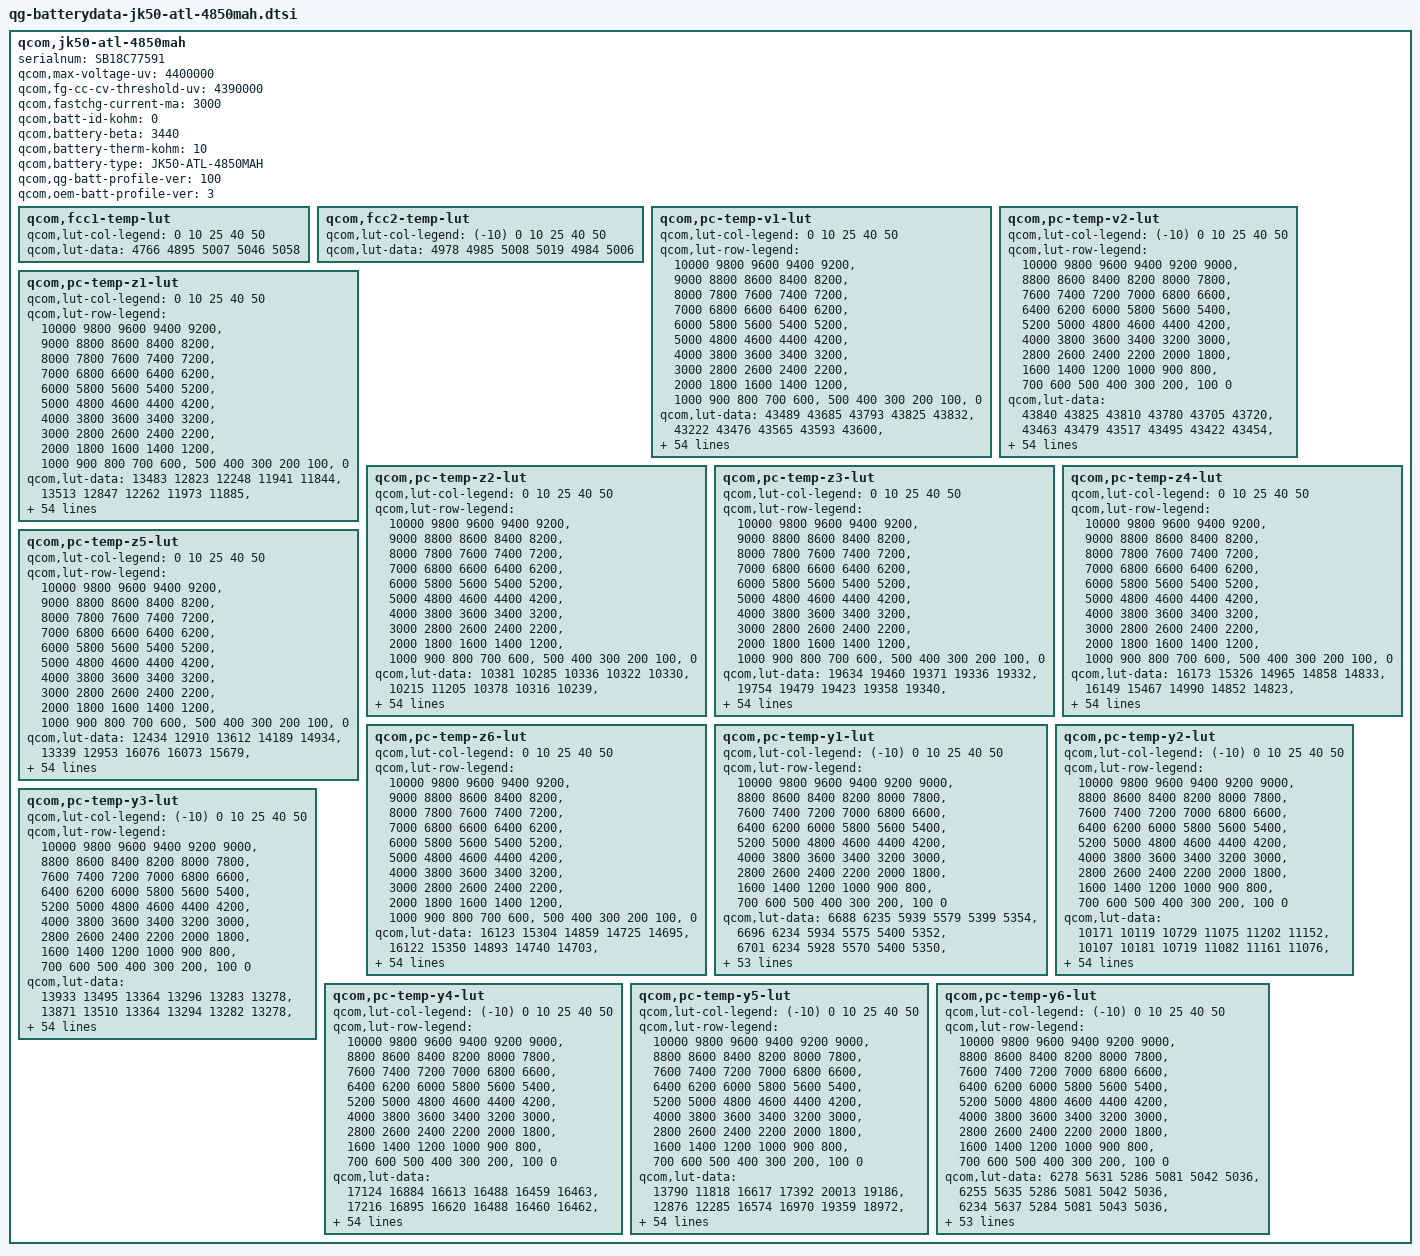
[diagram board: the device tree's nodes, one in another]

qcom,jk50-atl-4850mah {
    /* 4456891_ATL_P270AE_SCUD_4850mAH_PMI632_averaged_MasterSlave_Apr8th2020 */
    serialnum = "SB18C77591";
    qcom,max-voltage-uv = <4400000>;
    qcom,fg-cc-cv-threshold-uv = <4390000>;
    qcom,fastchg-current-ma = <3000>;
    qcom,batt-id-kohm = <0>;
    qcom,battery-beta = <3440>;
    qcom,battery-therm-kohm = <10>;
    qcom,battery-type = "JK50-ATL-4850MAH";
    qcom,qg-batt-profile-ver = <100>;
    qcom,oem-batt-profile-ver = <3>;

	qcom,fcc1-temp-lut {
		qcom,lut-col-legend = <0 10 25 40 50>;
		qcom,lut-data = <4766 4895 5007 5046 5058>;
	};

	qcom,fcc2-temp-lut {
		qcom,lut-col-legend = <(-10) 0 10 25 40 50>;
		qcom,lut-data = <4978 4985 5008 5019 4984 5006>;
	};

	qcom,pc-temp-v1-lut {
		qcom,lut-col-legend = <0 10 25 40 50>;
		qcom,lut-row-legend = <10000 9800 9600 9400 9200>,
			<9000 8800 8600 8400 8200>,
			<8000 7800 7600 7400 7200>,
			<7000 6800 6600 6400 6200>,
			<6000 5800 5600 5400 5200>,
			<5000 4800 4600 4400 4200>,
			<4000 3800 3600 3400 3200>,
			<3000 2800 2600 2400 2200>,
			<2000 1800 1600 1400 1200>,
			<1000 900 800 700 600>,
			<500 400 300 200 100>,
			<0>;
		qcom,lut-data = <43489 43685 43793 43825 43832>,
			<43222 43476 43565 43593 43600>,
			<42969 43219 43335 43369 43384>,
			<42729 42960 43094 43140 43159>,
			<42498 42718 42852 42907 42927>,
			<42272 42482 42613 42674 42696>,
			<42050 42251 42378 42440 42464>,
			<41833 42025 42145 42206 42233>,
			<41616 41803 41915 41975 42002>,
			<41407 41581 41689 41747 41772>,
			<41218 41366 41466 41521 41546>,
			<41046 41172 41250 41300 41326>,
			<40852 40998 41044 41086 41109>,
			<40601 40807 40847 40883 40898>,
			<40340 40566 40644 40681 40692>,
			<40134 40321 40429 40471 40491>,
			<39963 40127 40224 40267 40298>,
			<39809 39962 40050 40090 40118>,
			<39671 39812 39892 39931 39950>,
			<39543 39678 39739 39773 39785>,
			<39416 39547 39597 39618 39628>,
			<39293 39401 39429 39449 39462>,
			<39172 39246 39164 39216 39242>,
			<39053 39071 38884 38950 38983>,
			<38937 38840 38735 38781 38807>,
			<38821 38633 38640 38678 38699>,
			<38703 38527 38560 38589 38606>,
			<38594 38455 38486 38499 38507>,
			<38498 38398 38419 38414 38413>,
			<38410 38351 38354 38332 38326>,
			<38347 38310 38295 38255 38245>,
			<38301 38270 38241 38187 38172>,
			<38262 38233 38191 38130 38109>,
			<38227 38198 38145 38077 38050>,
			<38196 38167 38101 38023 37992>,
			<38163 38134 38058 37971 37936>,
			<38131 38098 38014 37920 37878>,
			<38094 38058 37971 37874 37822>,
			<38042 38002 37915 37817 37757>,
			<37969 37917 37827 37732 37668>,
			<37880 37814 37718 37624 37560>,
			<37760 37698 37604 37509 37444>,
			<37622 37562 37477 37380 37314>,
			<37464 37402 37322 37228 37162>,
			<37330 37256 37176 37087 37022>,
			<37233 37167 37080 36996 36939>,
			<37204 37137 37056 36967 36911>,
			<37178 37114 37037 36951 36892>,
			<37159 37099 37022 36933 36871>,
			<37110 37052 36975 36873 36806>,
			<36889 36824 36740 36623 36542>,
			<36444 36392 36311 36185 36099>,
			<35865 35818 35740 35608 35527>,
			<35077 35035 34961 34821 34744>,
			<33839 33806 33753 33601 33539>,
			<30000 30000 30000 30000 30000>;
	};

	qcom,pc-temp-v2-lut {
		qcom,lut-col-legend = <(-10) 0 10 25 40 50>;
		qcom,lut-row-legend = <10000 9800 9600 9400 9200 9000>,
			<8800 8600 8400 8200 8000 7800>,
			<7600 7400 7200 7000 6800 6600>,
			<6400 6200 6000 5800 5600 5400>,
			<5200 5000 4800 4600 4400 4200>,
			<4000 3800 3600 3400 3200 3000>,
			<2800 2600 2400 2200 2000 1800>,
			<1600 1400 1200 1000 900 800>,
			<700 600 500 400 300 200>,
			<100 0>;
		qcom,lut-data = <43840 43825 43810 43780 43705 43720>,
			<43463 43479 43517 43495 43422 43454>,
			<43120 43162 43238 43225 43155 43197>,
			<42814 42878 42975 42971 42904 42952>,
			<42537 42625 42728 42733 42668 42718>,
			<42295 42378 42485 42497 42435 42485>,
			<42098 42133 42245 42263 42201 42251>,
			<41907 41893 42009 42030 41970 42018>,
			<41651 41655 41779 41800 41742 41789>,
			<41347 41421 41553 41573 41517 41562>,
			<41151 41211 41334 41348 41296 41339>,
			<41063 41036 41124 41129 41077 41120>,
			<40966 40861 40919 40914 40864 40905>,
			<40674 40665 40722 40711 40663 40698>,
			<40191 40451 40526 40512 40468 40497>,
			<39844 40198 40321 40307 40275 40303>,
			<39603 39874 40109 40096 40079 40116>,
			<39403 39591 39891 39905 39896 39938>,
			<39234 39410 39661 39754 39738 39773>,
			<39085 39260 39432 39605 39586 39610>,
			<38920 39094 39227 39404 39400 39422>,
			<38741 38920 39037 39156 39174 39210>,
			<38584 38758 38867 38941 38965 39009>,
			<38454 38616 38711 38764 38779 38814>,
			<38342 38481 38572 38612 38616 38641>,
			<38255 38341 38452 38489 38488 38510>,
			<38184 38199 38346 38385 38383 38402>,
			<38117 38102 38246 38288 38288 38302>,
			<38053 38041 38152 38199 38202 38211>,
			<37992 37993 38065 38117 38124 38127>,
			<37936 37946 37984 38043 38053 38054>,
			<37882 37903 37911 37973 37987 37985>,
			<37828 37860 37858 37908 37923 37920>,
			<37772 37816 37817 37847 37860 37858>,
			<37716 37772 37779 37789 37794 37788>,
			<37656 37727 37741 37734 37715 37697>,
			<37592 37679 37702 37676 37629 37598>,
			<37525 37624 37658 37610 37547 37501>,
			<37452 37561 37607 37536 37466 37406>,
			<37380 37490 37543 37459 37385 37318>,
			<37312 37405 37455 37379 37308 37242>,
			<37243 37307 37347 37283 37220 37155>,
			<37175 37192 37216 37157 37107 37047>,
			<37103 37070 37080 37023 36975 36909>,
			<37019 36957 36947 36912 36862 36799>,
			<36927 36856 36869 36872 36817 36761>,
			<36870 36817 36837 36848 36804 36749>,
			<36813 36776 36801 36829 36788 36737>,
			<36736 36725 36754 36783 36764 36709>,
			<36596 36632 36658 36647 36687 36617>,
			<36345 36426 36430 36288 36414 36304>,
			<35926 36021 35974 35763 35937 35816>,
			<35317 35415 35343 35066 35318 35179>,
			<34420 34552 34477 34037 34481 34304>,
			<33052 33166 33168 32764 33241 33030>,
			<28345 27965 27983 27933 28174 28632>;
	};

	qcom,pc-temp-z1-lut {
		qcom,lut-col-legend = <0 10 25 40 50>;
		qcom,lut-row-legend = <10000 9800 9600 9400 9200>,
			<9000 8800 8600 8400 8200>,
			<8000 7800 7600 7400 7200>,
			<7000 6800 6600 6400 6200>,
			<6000 5800 5600 5400 5200>,
			<5000 4800 4600 4400 4200>,
			<4000 3800 3600 3400 3200>,
			<3000 2800 2600 2400 2200>,
			<2000 1800 1600 1400 1200>,
			<1000 900 800 700 600>,
			<500 400 300 200 100>,
			<0>;
		qcom,lut-data = <13483 12823 12248 11941 11844>,
			<13513 12847 12262 11973 11885>,
			<13517 12846 12273 11976 11893>,
			<13493 12843 12259 11973 11890>,
			<13470 12841 12245 11968 11887>,
			<13462 12839 12235 11964 11886>,
			<13455 12834 12226 11962 11885>,
			<13448 12813 12218 11960 11885>,
			<13441 12795 12210 11958 11886>,
			<13435 12787 12206 11956 11887>,
			<13436 12779 12203 11956 11889>,
			<13443 12774 12200 11958 11892>,
			<13440 12764 12198 11958 11893>,
			<13400 12754 12196 11956 11893>,
			<13354 12743 12193 11955 11893>,
			<13342 12733 12189 11955 11892>,
			<13341 12728 12187 11957 11892>,
			<13342 12720 12188 11959 11893>,
			<13343 12717 12191 11961 11895>,
			<13342 12720 12195 11962 11896>,
			<13337 12727 12201 11963 11897>,
			<13324 12735 12205 11963 11898>,
			<13317 12748 12206 11965 11899>,
			<13317 12753 12206 11968 11901>,
			<13318 12749 12208 11970 11902>,
			<13322 12746 12214 11972 11904>,
			<13339 12748 12220 11974 11906>,
			<13352 12754 12225 11976 11909>,
			<13354 12757 12230 11979 11913>,
			<13356 12759 12234 11983 11916>,
			<13357 12761 12238 11988 11919>,
			<13357 12766 12242 11993 11923>,
			<13357 12776 12247 11998 11926>,
			<13361 12781 12252 12002 11930>,
			<13365 12786 12259 12005 11933>,
			<13370 12789 12267 12008 11937>,
			<13376 12793 12274 12011 11941>,
			<13383 12799 12281 12016 11944>,
			<13390 12807 12288 12022 11947>,
			<13409 12816 12295 12026 11950>,
			<13420 12828 12301 12031 11953>,
			<13436 12847 12307 12035 11956>,
			<13445 12862 12313 12039 11958>,
			<13456 12858 12322 12043 11960>,
			<13449 12859 12335 12048 11963>,
			<13460 12875 12339 12053 11967>,
			<13457 12871 12341 12052 11967>,
			<13449 12866 12346 12054 11967>,
			<13462 12859 12349 12057 11970>,
			<13470 12883 12352 12057 11973>,
			<13452 12894 12361 12063 11977>,
			<13463 12890 12370 12074 11988>,
			<13506 12936 12393 12083 11996>,
			<13511 12988 12410 12102 12009>,
			<13511 12988 12410 12102 12009>,
			<13511 12988 12410 12102 12009>;
	};

	qcom,pc-temp-z2-lut {
		qcom,lut-col-legend = <0 10 25 40 50>;
		qcom,lut-row-legend = <10000 9800 9600 9400 9200>,
			<9000 8800 8600 8400 8200>,
			<8000 7800 7600 7400 7200>,
			<7000 6800 6600 6400 6200>,
			<6000 5800 5600 5400 5200>,
			<5000 4800 4600 4400 4200>,
			<4000 3800 3600 3400 3200>,
			<3000 2800 2600 2400 2200>,
			<2000 1800 1600 1400 1200>,
			<1000 900 800 700 600>,
			<500 400 300 200 100>,
			<0>;
		qcom,lut-data = <10381 10285 10336 10322 10330>,
			<10215 11205 10378 10316 10239>,
			<10177 10527 10398 10428 10314>,
			<10201 10289 10410 10462 10365>,
			<10233 10261 10416 10477 10496>,
			<10262 10240 10410 10483 10519>,
			<10291 10226 10398 10476 10488>,
			<10302 10214 10386 10465 10456>,
			<10300 10205 10370 10447 10428>,
			<10297 10196 10359 10428 10405>,
			<10292 10190 10354 10412 10399>,
			<10280 10197 10350 10395 10396>,
			<10264 10236 10354 10392 10388>,
			<10205 10262 10369 10409 10370>,
			<10139 10244 10381 10424 10362>,
			<10132 10216 10388 10441 10399>,
			<10159 10223 10394 10460 10446>,
			<10179 10258 10403 10438 10425>,
			<10167 10292 10416 10351 10354>,
			<10146 10322 10437 10317 10324>,
			<10139 10346 10477 10402 10380>,
			<10136 10360 10499 10493 10443>,
			<10135 10369 10488 10504 10438>,
			<10139 10378 10472 10498 10407>,
			<10150 10388 10467 10476 10399>,
			<10160 10396 10467 10415 10405>,
			<10172 10397 10471 10378 10419>,
			<10184 10398 10492 10409 10521>,
			<10195 10398 10517 10470 10662>,
			<10205 10399 10532 10524 10677>,
			<10214 10400 10544 10583 10648>,
			<10219 10404 10547 10602 10596>,
			<10226 10410 10543 10546 10496>,
			<10236 10417 10540 10491 10404>,
			<10251 10425 10538 10493 10366>,
			<10266 10434 10537 10507 10338>,
			<10279 10441 10539 10523 10337>,
			<10292 10449 10547 10546 10388>,
			<10304 10459 10559 10567 10441>,
			<10315 10473 10586 10588 10467>,
			<10328 10485 10614 10609 10489>,
			<10340 10490 10619 10621 10516>,
			<10358 10495 10619 10636 10547>,
			<10399 10510 10628 10620 10545>,
			<10669 10613 10672 10589 10539>,
			<10792 10758 10724 10570 10496>,
			<10736 10766 10679 10552 10480>,
			<10778 10775 10683 10572 10441>,
			<10606 10984 10721 10601 10491>,
			<10579 10969 10759 10639 10570>,
			<10662 10887 10793 10626 10430>,
			<10510 10869 10701 10447 10245>,
			<10275 10784 10644 10369 10179>,
			<10118 10619 10546 10287 10103>,
			<10118 10619 10546 10287 10103>,
			<10118 10619 10546 10287 10103>;
	};

	qcom,pc-temp-z3-lut {
		qcom,lut-col-legend = <0 10 25 40 50>;
		qcom,lut-row-legend = <10000 9800 9600 9400 9200>,
			<9000 8800 8600 8400 8200>,
			<8000 7800 7600 7400 7200>,
			<7000 6800 6600 6400 6200>,
			<6000 5800 5600 5400 5200>,
			<5000 4800 4600 4400 4200>,
			<4000 3800 3600 3400 3200>,
			<3000 2800 2600 2400 2200>,
			<2000 1800 1600 1400 1200>,
			<1000 900 800 700 600>,
			<500 400 300 200 100>,
			<0>;
		qcom,lut-data = <19634 19460 19371 19336 19332>,
			<19754 19479 19423 19358 19340>,
			<19799 19578 19452 19386 19359>,
			<19809 19631 19469 19396 19378>,
			<19813 19638 19476 19401 19389>,
			<19797 19641 19476 19405 19392>,
			<19753 19640 19475 19408 19393>,
			<19728 19633 19474 19409 19394>,
			<19719 19627 19474 19409 19396>,
			<19714 19622 19473 19408 19398>,
			<19710 19617 19469 19406 19396>,
			<19701 19616 19462 19400 19389>,
			<19699 19626 19455 19395 19384>,
			<19742 19635 19446 19390 19380>,
			<19796 19622 19441 19387 19378>,
			<19809 19599 19439 19388 19377>,
			<19809 19582 19438 19389 19373>,
			<19805 19563 19433 19386 19369>,
			<19779 19548 19426 19375 19361>,
			<19742 19533 19424 19369 19356>,
			<19732 19522 19423 19368 19353>,
			<19732 19526 19424 19368 19351>,
			<19733 19541 19432 19369 19350>,
			<19734 19555 19442 19370 19350>,
			<19735 19570 19441 19369 19347>,
			<19738 19580 19432 19358 19337>,
			<19744 19579 19427 19351 19329>,
			<19748 19576 19425 19352 19341>,
			<19747 19571 19425 19356 19363>,
			<19743 19566 19426 19365 19374>,
			<19737 19559 19429 19384 19385>,
			<19725 19554 19432 19392 19390>,
			<19711 19549 19434 19391 19385>,
			<19699 19544 19435 19389 19378>,
			<19688 19539 19435 19387 19371>,
			<19677 19535 19434 19383 19364>,
			<19666 19533 19432 19379 19359>,
			<19656 19532 19426 19373 19355>,
			<19651 19529 19423 19368 19352>,
			<19647 19527 19422 19365 19349>,
			<19642 19523 19422 19364 19346>,
			<19636 19519 19419 19363 19347>,
			<19627 19513 19413 19364 19352>,
			<19610 19506 19410 19364 19356>,
			<19522 19484 19403 19360 19357>,
			<19476 19439 19391 19348 19342>,
			<19411 19431 19384 19348 19336>,
			<19395 19426 19380 19341 19331>,
			<19315 19352 19356 19332 19324>,
			<19313 19380 19351 19328 19322>,
			<19333 19418 19357 19339 19346>,
			<19345 19404 19370 19354 19359>,
			<19347 19375 19370 19349 19356>,
			<19353 19332 19368 19353 19354>,
			<19353 19332 19368 19353 19354>,
			<19353 19332 19368 19353 19354>;
	};

	qcom,pc-temp-z4-lut {
		qcom,lut-col-legend = <0 10 25 40 50>;
		qcom,lut-row-legend = <10000 9800 9600 9400 9200>,
			<9000 8800 8600 8400 8200>,
			<8000 7800 7600 7400 7200>,
			<7000 6800 6600 6400 6200>,
			<6000 5800 5600 5400 5200>,
			<5000 4800 4600 4400 4200>,
			<4000 3800 3600 3400 3200>,
			<3000 2800 2600 2400 2200>,
			<2000 1800 1600 1400 1200>,
			<1000 900 800 700 600>,
			<500 400 300 200 100>,
			<0>;
		qcom,lut-data = <16173 15326 14965 14858 14833>,
			<16149 15467 14990 14852 14823>,
			<16087 15369 15057 14901 14851>,
			<15906 15259 14998 14885 14849>,
			<15709 15163 14933 14853 14827>,
			<15594 15071 14892 14828 14808>,
			<15505 15003 14858 14806 14790>,
			<15426 14950 14827 14786 14774>,
			<15354 14907 14799 14769 14758>,
			<15288 14874 14777 14753 14744>,
			<15228 14847 14760 14740 14732>,
			<15174 14815 14748 14729 14722>,
			<15118 14758 14737 14720 14714>,
			<15054 14722 14727 14712 14708>,
			<14991 14736 14721 14705 14702>,
			<14940 14760 14717 14699 14698>,
			<14888 14761 14714 14694 14693>,
			<14856 14754 14706 14688 14690>,
			<14852 14747 14694 14683 14685>,
			<14854 14742 14687 14681 14684>,
			<14845 14737 14681 14681 14684>,
			<14823 14730 14678 14682 14686>,
			<14800 14722 14737 14720 14718>,
			<14783 14721 14819 14802 14797>,
			<14769 14771 14831 14823 14821>,
			<14767 14822 14828 14821 14820>,
			<14767 14823 14824 14817 14817>,
			<14767 14814 14811 14806 14795>,
			<14771 14803 14793 14786 14758>,
			<14777 14790 14777 14763 14732>,
			<14778 14776 14761 14734 14708>,
			<14776 14765 14745 14713 14694>,
			<14772 14754 14729 14699 14687>,
			<14768 14744 14716 14690 14682>,
			<14763 14734 14706 14687 14682>,
			<14758 14725 14698 14685 14683>,
			<14754 14718 14695 14685 14683>,
			<14750 14712 14694 14684 14683>,
			<14745 14711 14694 14684 14683>,
			<14738 14715 14700 14691 14691>,
			<14735 14718 14707 14702 14704>,
			<14736 14717 14706 14701 14703>,
			<14736 14715 14703 14694 14694>,
			<14732 14713 14702 14695 14692>,
			<14737 14700 14695 14694 14688>,
			<14742 14694 14670 14674 14669>,
			<14811 14695 14669 14668 14669>,
			<14825 14695 14660 14659 14659>,
			<14909 14768 14674 14648 14642>,
			<14902 14730 14676 14649 14638>,
			<14880 14701 14692 14667 14649>,
			<14890 14728 14690 14667 14653>,
			<14902 14769 14696 14676 14661>,
			<14916 14829 14702 14677 14667>,
			<14916 14829 14702 14677 14667>,
			<14916 14829 14702 14677 14667>;
	};

	qcom,pc-temp-z5-lut {
		qcom,lut-col-legend = <0 10 25 40 50>;
		qcom,lut-row-legend = <10000 9800 9600 9400 9200>,
			<9000 8800 8600 8400 8200>,
			<8000 7800 7600 7400 7200>,
			<7000 6800 6600 6400 6200>,
			<6000 5800 5600 5400 5200>,
			<5000 4800 4600 4400 4200>,
			<4000 3800 3600 3400 3200>,
			<3000 2800 2600 2400 2200>,
			<2000 1800 1600 1400 1200>,
			<1000 900 800 700 600>,
			<500 400 300 200 100>,
			<0>;
		qcom,lut-data = <12434 12910 13612 14189 14934>,
			<13339 12953 16076 16073 15679>,
			<13842 14580 16323 17560 16811>,
			<14126 15938 17234 18038 18007>,
			<14271 16585 18085 18457 19363>,
			<14227 17053 18449 18840 19857>,
			<14096 17428 18733 19216 20034>,
			<14043 17749 19225 19591 20302>,
			<14146 18060 20096 20034 21135>,
			<14283 18692 20759 20490 21993>,
			<14314 19271 21127 20905 22180>,
			<14309 19934 21297 21297 22201>,
			<14442 23446 21306 21611 22478>,
			<15838 25797 21545 21927 23352>,
			<17690 25749 21949 22336 24030>,
			<18688 24904 22538 24105 24855>,
			<19782 23806 23093 26200 26070>,
			<20372 22430 23654 26182 26130>,
			<19714 21767 24564 25175 25709>,
			<18651 21497 25783 24831 25611>,
			<18706 21313 28660 27186 26461>,
			<20038 23276 32639 29552 27319>,
			<21879 30307 39656 29370 26766>,
			<24139 37849 46439 28396 24729>,
			<27106 47419 44685 26615 22276>,
			<30816 54604 34915 21797 18545>,
			<36391 52997 28593 18553 16266>,
			<40771 46769 26086 18142 17199>,
			<42486 41712 24774 17934 19128>,
			<43649 37983 24827 18744 21197>,
			<43597 35194 25227 22277 24895>,
			<40270 33601 25879 25391 27671>,
			<36170 32436 27528 27463 29185>,
			<33584 31867 29661 29313 30159>,
			<31412 31627 32432 31587 30473>,
			<29846 31688 35171 34001 30502>,
			<28477 32538 35564 34370 30300>,
			<27608 33897 35000 32846 30107>,
			<27932 34260 34353 30928 29818>,
			<29094 34169 33847 28914 27644>,
			<29800 33983 33266 26945 24483>,
			<29761 32629 31324 25755 23834>,
			<29479 30681 27678 24722 24193>,
			<29009 29936 26438 24283 25147>,
			<23811 29922 26504 23367 25874>,
			<20231 24124 27891 21656 21746>,
			<15956 22381 24978 22002 19859>,
			<15141 21264 24255 20668 19698>,
			<12189 14232 18875 20439 21041>,
			<12220 15969 17856 19481 21209>,
			<12774 20453 17715 18379 23315>,
			<12844 17373 18175 18879 23704>,
			<12645 15230 17098 17114 20036>,
			<12468 12685 16336 16737 17706>,
			<12468 12685 16336 16737 17706>,
			<12468 12685 16336 16737 17706>;
	};

	qcom,pc-temp-z6-lut {
		qcom,lut-col-legend = <0 10 25 40 50>;
		qcom,lut-row-legend = <10000 9800 9600 9400 9200>,
			<9000 8800 8600 8400 8200>,
			<8000 7800 7600 7400 7200>,
			<7000 6800 6600 6400 6200>,
			<6000 5800 5600 5400 5200>,
			<5000 4800 4600 4400 4200>,
			<4000 3800 3600 3400 3200>,
			<3000 2800 2600 2400 2200>,
			<2000 1800 1600 1400 1200>,
			<1000 900 800 700 600>,
			<500 400 300 200 100>,
			<0>;
		qcom,lut-data = <16123 15304 14859 14725 14695>,
			<16122 15350 14893 14740 14703>,
			<16099 15336 14933 14775 14725>,
			<16002 15315 14914 14771 14730>,
			<15883 15276 14890 14762 14729>,
			<15797 15218 14871 14754 14727>,
			<15720 15174 14853 14746 14720>,
			<15658 15139 14837 14737 14713>,
			<15610 15110 14823 14730 14708>,
			<15569 15088 14811 14722 14703>,
			<15528 15069 14801 14715 14696>,
			<15488 15047 14792 14708 14689>,
			<15457 15023 14782 14701 14683>,
			<15437 15006 14772 14695 14679>,
			<15419 14998 14766 14690 14675>,
			<15398 14990 14763 14688 14671>,
			<15374 14981 14760 14686 14667>,
			<15352 14969 14754 14681 14663>,
			<15332 14958 14746 14673 14657>,
			<15315 14949 14742 14669 14654>,
			<15301 14942 14740 14669 14652>,
			<15289 14943 14739 14669 14652>,
			<15281 14948 14768 14685 14665>,
			<15275 14957 14809 14722 14698>,
			<15271 14987 14814 14731 14709>,
			<15271 15015 14810 14726 14704>,
			<15277 15016 14806 14720 14698>,
			<15282 15012 14800 14715 14694>,
			<15284 15006 14794 14710 14691>,
			<15285 14999 14789 14706 14688>,
			<15285 14992 14785 14704 14684>,
			<15279 14985 14781 14701 14680>,
			<15271 14979 14776 14695 14675>,
			<15266 14974 14772 14690 14670>,
			<15261 14969 14769 14688 14667>,
			<15256 14966 14766 14686 14664>,
			<15251 14964 14764 14683 14661>,
			<15247 14964 14761 14680 14658>,
			<15248 14964 14761 14678 14657>,
			<15250 14969 14765 14680 14659>,
			<15253 14973 14770 14684 14663>,
			<15256 14974 14769 14684 14663>,
			<15258 14974 14766 14682 14662>,
			<15257 14974 14766 14683 14664>,
			<15232 14966 14763 14681 14664>,
			<15213 14946 14748 14667 14648>,
			<15209 14943 14744 14664 14645>,
			<15205 14940 14739 14657 14638>,
			<15202 14936 14733 14648 14627>,
			<15205 14937 14733 14647 14624>,
			<15214 14948 14745 14661 14643>,
			<15231 14959 14754 14671 14654>,
			<15252 14971 14761 14675 14658>,
			<15282 14990 14769 14681 14664>,
			<15282 14990 14769 14681 14664>,
			<15282 14990 14769 14681 14664>;
	};

	qcom,pc-temp-y1-lut {
		qcom,lut-col-legend = <(-10) 0 10 25 40 50>;
		qcom,lut-row-legend = <10000 9800 9600 9400 9200 9000>,
			<8800 8600 8400 8200 8000 7800>,
			<7600 7400 7200 7000 6800 6600>,
			<6400 6200 6000 5800 5600 5400>,
			<5200 5000 4800 4600 4400 4200>,
			<4000 3800 3600 3400 3200 3000>,
			<2800 2600 2400 2200 2000 1800>,
			<1600 1400 1200 1000 900 800>,
			<700 600 500 400 300 200>,
			<100 0>;
		qcom,lut-data = <6688 6235 5939 5579 5399 5354>,
			<6696 6234 5934 5575 5400 5352>,
			<6701 6234 5928 5570 5400 5350>,
			<6704 6234 5922 5566 5400 5348>,
			<6705 6234 5916 5562 5400 5346>,
			<6705 6234 5913 5558 5399 5344>,
			<6706 6232 5911 5554 5397 5342>,
			<6705 6229 5909 5550 5395 5341>,
			<6699 6230 5908 5546 5393 5340>,
			<6689 6233 5906 5544 5391 5340>,
			<6685 6236 5904 5541 5390 5340>,
			<6689 6238 5902 5538 5390 5339>,
			<6695 6240 5900 5536 5389 5339>,
			<6697 6244 5900 5534 5389 5338>,
			<6699 6249 5900 5532 5389 5338>,
			<6699 6251 5901 5532 5389 5338>,
			<6697 6250 5901 5533 5389 5338>,
			<6696 6249 5902 5535 5389 5338>,
			<6700 6255 5902 5536 5389 5336>,
			<6706 6262 5901 5538 5390 5335>,
			<6708 6262 5901 5538 5390 5335>,
			<6710 6256 5900 5538 5392 5337>,
			<6710 6252 5899 5539 5394 5338>,
			<6703 6255 5900 5546 5395 5340>,
			<6693 6260 5902 5552 5397 5342>,
			<6689 6261 5904 5553 5399 5344>,
			<6691 6263 5907 5553 5401 5348>,
			<6692 6263 5910 5554 5404 5350>,
			<6696 6259 5914 5558 5408 5352>,
			<6702 6254 5917 5563 5412 5354>,
			<6693 6250 5919 5567 5416 5356>,
			<6674 6246 5922 5571 5419 5358>,
			<6668 6244 5924 5575 5422 5360>,
			<6671 6245 5927 5579 5426 5362>,
			<6675 6246 5930 5583 5428 5365>,
			<6675 6246 5931 5585 5429 5367>,
			<6674 6246 5933 5588 5430 5370>,
			<6673 6244 5934 5590 5432 5371>,
			<6670 6241 5935 5594 5433 5372>,
			<6668 6240 5935 5595 5435 5373>,
			<6662 6244 5935 5595 5436 5376>,
			<6659 6245 5937 5597 5437 5377>,
			<6660 6237 5946 5600 5439 5375>,
			<6666 6236 5948 5608 5443 5379>,
			<6688 6252 5940 5615 5447 5384>,
			<6687 6252 5955 5627 5451 5389>,
			<6677 6264 5954 5626 5451 5388>,
			<6658 6260 5947 5625 5453 5385>,
			<6671 6246 5956 5626 5452 5384>,
			<6716 6259 5961 5629 5451 5386>,
			<6705 6272 5951 5632 5453 5389>,
			<6700 6275 5961 5645 5462 5393>,
			<6759 6278 5971 5669 5470 5400>,
			<6823 6311 6005 5701 5482 5409>,
			<6823 6311 6005 5701 5482 5409>,
			<6823 6311 6005 5701 5482 5409>;
	};

	qcom,pc-temp-y2-lut {
		qcom,lut-col-legend = <(-10) 0 10 25 40 50>;
		qcom,lut-row-legend = <10000 9800 9600 9400 9200 9000>,
			<8800 8600 8400 8200 8000 7800>,
			<7600 7400 7200 7000 6800 6600>,
			<6400 6200 6000 5800 5600 5400>,
			<5200 5000 4800 4600 4400 4200>,
			<4000 3800 3600 3400 3200 3000>,
			<2800 2600 2400 2200 2000 1800>,
			<1600 1400 1200 1000 900 800>,
			<700 600 500 400 300 200>,
			<100 0>;
		qcom,lut-data = <10171 10119 10729 11075 11202 11152>,
			<10107 10181 10719 11082 11161 11076>,
			<10085 10238 10707 11080 11109 11014>,
			<10097 10285 10695 11071 11053 10965>,
			<10130 10317 10685 11059 11000 10929>,
			<10176 10326 10680 11047 10957 10908>,
			<10255 10310 10678 11027 10908 10905>,
			<10347 10291 10677 11006 10871 10911>,
			<10422 10319 10685 10991 10891 10924>,
			<10491 10419 10706 10977 10958 10947>,
			<10527 10504 10716 10974 10981 10954>,
			<10540 10571 10719 10981 10939 10944>,
			<10555 10627 10723 10991 10900 10928>,
			<10638 10665 10791 11009 10923 10904>,
			<10782 10697 10915 11040 10977 10876>,
			<10742 10734 10963 11078 11002 10880>,
			<10139 10777 10983 11138 11015 10947>,
			<9691 10828 10994 11194 11036 11013>,
			<9683 10915 11003 11244 11123 11059>,
			<9680 11004 11018 11279 11236 11110>,
			<9678 11032 11039 11275 11273 11187>,
			<9676 11040 11078 11255 11290 11326>,
			<9675 11033 11112 11248 11295 11381>,
			<9673 10977 11133 11257 11254 11332>,
			<9671 10913 11156 11270 11202 11269>,
			<9670 10906 11196 11279 11195 11226>,
			<9669 10912 11246 11285 11198 11187>,
			<9668 10878 11257 11296 11211 11184>,
			<9667 10334 11241 11340 11283 11237>,
			<9667 9798 11229 11382 11364 11281>,
			<9666 9738 11233 11403 11421 11293>,
			<9665 9715 11238 11421 11480 11301>,
			<9665 9701 11236 11437 11492 11301>,
			<9664 9692 11216 11460 11445 11293>,
			<9664 9686 11193 11471 11409 11289>,
			<9663 9681 11169 11463 11413 11309>,
			<9663 9678 11141 11446 11420 11333>,
			<9663 9674 11113 11410 11405 11323>,
			<9662 9671 11084 11354 11325 11272>,
			<9662 9669 11047 11340 11278 11235>,
			<9662 9667 10998 11359 11282 11231>,
			<9661 9665 10875 11358 11284 11211>,
			<9661 9664 10350 11306 11273 11160>,
			<9661 9662 10722 11252 11280 11185>,
			<9661 9662 10652 11235 11200 11024>,
			<9660 9660 10331 11185 11136 10925>,
			<9660 9660 10039 11154 11123 10861>,
			<9660 9659 9910 11133 11118 10930>,
			<9659 9659 9796 11161 11176 11016>,
			<9659 9658 9749 11165 11144 11026>,
			<9658 9657 9725 11090 11074 10865>,
			<9657 9657 9691 11019 11012 10807>,
			<9654 9656 9672 10944 10922 10731>,
			<9651 9654 9663 10832 10876 10667>,
			<9651 9654 9663 10832 10876 10667>,
			<9651 9654 9663 10832 10876 10667>;
	};

	qcom,pc-temp-y3-lut {
		qcom,lut-col-legend = <(-10) 0 10 25 40 50>;
		qcom,lut-row-legend = <10000 9800 9600 9400 9200 9000>,
			<8800 8600 8400 8200 8000 7800>,
			<7600 7400 7200 7000 6800 6600>,
			<6400 6200 6000 5800 5600 5400>,
			<5200 5000 4800 4600 4400 4200>,
			<4000 3800 3600 3400 3200 3000>,
			<2800 2600 2400 2200 2000 1800>,
			<1600 1400 1200 1000 900 800>,
			<700 600 500 400 300 200>,
			<100 0>;
		qcom,lut-data = <13933 13495 13364 13296 13283 13278>,
			<13871 13510 13364 13294 13282 13278>,
			<13819 13519 13365 13293 13282 13279>,
			<13780 13523 13366 13293 13282 13279>,
			<13755 13525 13368 13294 13283 13279>,
			<13748 13525 13368 13295 13283 13280>,
			<13766 13518 13369 13297 13284 13280>,
			<13786 13509 13370 13299 13285 13281>,
			<13736 13513 13370 13300 13286 13282>,
			<13582 13528 13370 13300 13287 13283>,
			<13523 13529 13370 13301 13288 13284>,
			<13533 13469 13371 13303 13287 13284>,
			<13542 13415 13371 13304 13287 13285>,
			<13538 13427 13368 13305 13289 13285>,
			<13526 13456 13362 13306 13293 13285>,
			<13510 13460 13361 13306 13294 13286>,
			<13482 13438 13362 13304 13292 13288>,
			<13465 13417 13363 13304 13290 13290>,
			<13473 13406 13357 13305 13291 13290>,
			<13485 13398 13349 13308 13292 13291>,
			<13487 13385 13343 13307 13291 13290>,
			<13485 13368 13339 13303 13289 13287>,
			<13483 13360 13334 13300 13287 13284>,
			<13478 13360 13328 13295 13284 13281>,
			<13474 13361 13323 13292 13282 13279>,
			<13478 13354 13322 13291 13281 13279>,
			<13497 13336 13321 13292 13280 13278>,
			<13516 13329 13320 13292 13280 13278>,
			<13532 13337 13320 13292 13280 13277>,
			<13549 13348 13319 13293 13281 13276>,
			<13570 13357 13317 13293 13282 13277>,
			<13593 13367 13314 13293 13282 13277>,
			<13618 13375 13313 13293 13283 13278>,
			<13643 13381 13315 13293 13283 13279>,
			<13670 13388 13317 13293 13283 13279>,
			<13696 13399 13319 13294 13282 13279>,
			<13723 13415 13322 13295 13282 13279>,
			<13753 13435 13325 13294 13282 13279>,
			<13787 13460 13328 13292 13281 13278>,
			<13822 13488 13330 13292 13281 13278>,
			<13856 13521 13330 13295 13282 13281>,
			<13892 13560 13330 13296 13284 13282>,
			<13933 13607 13326 13293 13284 13282>,
			<13967 13664 13331 13291 13282 13279>,
			<13927 13659 13327 13291 13282 13278>,
			<14006 13758 13334 13298 13285 13284>,
			<14052 13822 13338 13298 13289 13286>,
			<14118 13894 13350 13305 13292 13291>,
			<14184 13964 13372 13309 13296 13293>,
			<14262 14029 13394 13311 13296 13291>,
			<14378 14094 13415 13307 13291 13287>,
			<14552 14187 13444 13312 13290 13287>,
			<15017 14358 13529 13321 13293 13290>,
			<16301 14670 13714 13334 13301 13298>,
			<16301 14670 13714 13334 13301 13298>,
			<16301 14670 13714 13334 13301 13298>;
	};

	qcom,pc-temp-y4-lut {
		qcom,lut-col-legend = <(-10) 0 10 25 40 50>;
		qcom,lut-row-legend = <10000 9800 9600 9400 9200 9000>,
			<8800 8600 8400 8200 8000 7800>,
			<7600 7400 7200 7000 6800 6600>,
			<6400 6200 6000 5800 5600 5400>,
			<5200 5000 4800 4600 4400 4200>,
			<4000 3800 3600 3400 3200 3000>,
			<2800 2600 2400 2200 2000 1800>,
			<1600 1400 1200 1000 900 800>,
			<700 600 500 400 300 200>,
			<100 0>;
		qcom,lut-data = <17124 16884 16613 16488 16459 16463>,
			<17216 16895 16620 16488 16460 16462>,
			<17271 16905 16628 16489 16461 16462>,
			<17299 16915 16636 16489 16462 16462>,
			<17308 16925 16641 16490 16464 16462>,
			<17308 16934 16643 16491 16465 16463>,
			<17222 16945 16641 16492 16466 16463>,
			<17122 16953 16640 16492 16468 16464>,
			<17181 16936 16641 16495 16470 16466>,
			<17384 16885 16648 16501 16472 16467>,
			<17484 16878 16656 16507 16476 16469>,
			<17508 17055 16665 16513 16482 16472>,
			<17519 17215 16678 16520 16489 16476>,
			<17364 17181 16724 16530 16493 16481>,
			<17026 17081 16788 16546 16496 16488>,
			<16939 16982 16798 16562 16501 16493>,
			<16987 16867 16780 16579 16512 16497>,
			<17022 16801 16753 16596 16526 16503>,
			<16993 16795 16704 16619 16549 16519>,
			<16929 16792 16647 16637 16572 16537>,
			<16869 16782 16611 16619 16570 16537>,
			<16802 16757 16584 16555 16543 16530>,
			<16764 16726 16569 16512 16514 16519>,
			<16752 16681 16560 16488 16485 16489>,
			<16745 16637 16555 16476 16463 16463>,
			<16741 16611 16552 16477 16462 16462>,
			<16738 16591 16549 16479 16465 16463>,
			<16738 16586 16544 16481 16469 16466>,
			<16740 16603 16535 16485 16475 16472>,
			<16742 16624 16527 16490 16482 16480>,
			<16742 16632 16522 16496 16490 16489>,
			<16742 16638 16518 16502 16499 16497>,
			<16742 16644 16519 16506 16505 16505>,
			<16744 16655 16528 16508 16508 16511>,
			<16745 16665 16538 16509 16509 16514>,
			<16746 16675 16549 16507 16500 16503>,
			<16746 16683 16561 16502 16483 16486>,
			<16746 16690 16573 16498 16475 16476>,
			<16744 16695 16585 16494 16472 16469>,
			<16745 16697 16590 16493 16470 16467>,
			<16748 16695 16591 16494 16475 16473>,
			<16756 16689 16593 16495 16479 16477>,
			<16773 16677 16610 16498 16477 16478>,
			<16788 16665 16578 16491 16467 16460>,
			<16761 16644 16556 16475 16450 16445>,
			<16774 16659 16579 16487 16462 16459>,
			<16792 16675 16605 16509 16474 16482>,
			<16810 16697 16635 16530 16500 16514>,
			<16829 16733 16673 16558 16534 16547>,
			<16839 16772 16716 16563 16550 16552>,
			<16831 16790 16733 16529 16499 16485>,
			<16815 16767 16728 16531 16477 16474>,
			<16870 16757 16751 16559 16483 16477>,
			<17226 16797 16815 16624 16502 16488>,
			<17226 16797 16815 16624 16502 16488>,
			<17226 16797 16815 16624 16502 16488>;
	};

	qcom,pc-temp-y5-lut {
		qcom,lut-col-legend = <(-10) 0 10 25 40 50>;
		qcom,lut-row-legend = <10000 9800 9600 9400 9200 9000>,
			<8800 8600 8400 8200 8000 7800>,
			<7600 7400 7200 7000 6800 6600>,
			<6400 6200 6000 5800 5600 5400>,
			<5200 5000 4800 4600 4400 4200>,
			<4000 3800 3600 3400 3200 3000>,
			<2800 2600 2400 2200 2000 1800>,
			<1600 1400 1200 1000 900 800>,
			<700 600 500 400 300 200>,
			<100 0>;
		qcom,lut-data = <13790 11818 16617 17392 20013 19186>,
			<12876 12285 16574 16970 19359 18972>,
			<12477 12963 16621 16537 18692 18706>,
			<12497 13665 16708 16132 18067 18408>,
			<12839 14203 16788 15795 17538 18102>,
			<13450 14393 16815 15581 17160 17807>,
			<16167 14337 16849 15869 16895 17478>,
			<19003 14271 16879 16193 16689 17169>,
			<17852 14554 16770 15968 16549 16963>,
			<13753 15342 16438 15534 16467 16798>,
			<12343 15543 16069 15238 16281 16582>,
			<14900 14320 15564 15105 15523 16274>,
			<17886 13212 15245 15084 14886 15913>,
			<19314 15757 15394 14827 15103 15409>,
			<20334 21129 15869 14333 15598 14897>,
			<20055 22108 17139 14238 15614 14866>,
			<16255 19102 21017 14390 14809 15242>,
			<13458 16990 23240 14685 14241 15471>,
			<14248 17552 22541 16322 14383 15353>,
			<15554 18472 21513 18852 14781 15185>,
			<15738 18746 21218 21275 16097 16012>,
			<15410 18825 21144 23820 19961 19000>,
			<14937 19009 20938 24385 21942 20382>,
			<13951 21653 19666 21559 21265 20431>,
			<12989 24688 18453 18861 20105 20404>,
			<12902 22941 18620 18679 18976 19880>,
			<12945 16744 19345 19029 17686 18566>,
			<12961 14000 20238 19055 17277 17449>,
			<12936 13642 21647 19425 17473 16389>,
			<12911 13478 22502 19883 17794 15835>,
			<12983 13601 21070 20309 18209 15965>,
			<13194 13922 18762 20851 18795 16286>,
			<13382 14037 18406 21247 19321 16747>,
			<13570 14054 18661 21787 19872 17632>,
			<13679 14083 18960 22356 20427 18681>,
			<13684 14204 19256 23027 21158 20123>,
			<13682 14382 19590 23471 21878 21296>,
			<13645 14506 20019 22664 21628 20875>,
			<13451 14639 20526 20418 19972 19330>,
			<13279 14725 20667 19389 19101 18891>,
			<13199 14706 20185 20362 19508 20333>,
			<13141 14631 19108 20484 19952 20982>,
			<13064 14507 16565 18172 20643 20986>,
			<13126 14259 17820 17525 19231 20337>,
			<13081 14187 16558 18582 19820 18224>,
			<13493 13634 15922 18957 17541 17753>,
			<13408 13649 14597 16781 18099 17324>,
			<13795 13864 14181 17954 18076 17656>,
			<14176 14272 14512 18297 18378 17249>,
			<14384 14556 14987 19004 17860 16570>,
			<14368 14603 15165 18802 18071 16932>,
			<13975 14295 14334 20610 18731 17105>,
			<13056 13942 14106 21907 18814 17270>,
			<11607 13157 14040 21853 22867 21739>,
			<11607 13157 14040 21853 22867 21739>,
			<11607 13157 14040 21853 22867 21739>;
	};

	qcom,pc-temp-y6-lut {
		qcom,lut-col-legend = <(-10) 0 10 25 40 50>;
		qcom,lut-row-legend = <10000 9800 9600 9400 9200 9000>,
			<8800 8600 8400 8200 8000 7800>,
			<7600 7400 7200 7000 6800 6600>,
			<6400 6200 6000 5800 5600 5400>,
			<5200 5000 4800 4600 4400 4200>,
			<4000 3800 3600 3400 3200 3000>,
			<2800 2600 2400 2200 2000 1800>,
			<1600 1400 1200 1000 900 800>,
			<700 600 500 400 300 200>,
			<100 0>;
		qcom,lut-data = <6278 5631 5286 5081 5042 5036>,
			<6255 5635 5286 5081 5042 5036>,
			<6234 5637 5284 5081 5043 5036>,
			<6214 5636 5282 5081 5044 5036>,
			<6196 5634 5280 5081 5045 5036>,
			<6180 5631 5277 5081 5045 5037>,
			<6169 5626 5274 5082 5046 5037>,
			<6157 5618 5271 5083 5047 5038>,
			<6131 5610 5268 5085 5048 5039>,
			<6091 5602 5267 5086 5050 5040>,
			<6079 5600 5266 5088 5051 5042>,
			<6097 5609 5267 5090 5053 5043>,
			<6114 5617 5268 5092 5054 5044>,
			<6077 5615 5276 5096 5057 5046>,
			<5990 5609 5288 5101 5060 5048>,
			<5946 5595 5290 5106 5063 5050>,
			<5926 5551 5287 5109 5065 5053>,
			<5915 5520 5280 5113 5067 5055>,
			<5912 5518 5263 5121 5074 5061>,
			<5910 5516 5240 5127 5081 5065>,
			<5904 5511 5226 5121 5080 5065>,
			<5889 5499 5216 5100 5070 5061>,
			<5881 5492 5209 5085 5060 5055>,
			<5882 5490 5203 5076 5050 5044>,
			<5884 5488 5200 5070 5042 5035>,
			<5892 5485 5200 5071 5041 5035>,
			<5910 5482 5201 5072 5042 5035>,
			<5929 5482 5202 5073 5043 5035>,
			<5945 5498 5203 5075 5045 5037>,
			<5961 5522 5203 5077 5048 5039>,
			<5978 5542 5204 5080 5051 5042>,
			<5996 5563 5206 5083 5055 5045>,
			<6015 5584 5210 5085 5057 5047>,
			<6036 5607 5219 5086 5058 5050>,
			<6057 5631 5230 5087 5059 5051>,
			<6080 5657 5241 5088 5056 5048>,
			<6104 5686 5254 5088 5052 5044>,
			<6128 5717 5268 5087 5049 5041>,
			<6154 5751 5284 5085 5048 5038>,
			<6181 5786 5299 5085 5047 5038>,
			<6208 5821 5313 5088 5050 5042>,
			<6239 5859 5328 5090 5052 5044>,
			<6275 5902 5344 5090 5052 5044>,
			<6311 5951 5360 5088 5048 5038>,
			<6284 5947 5354 5085 5044 5033>,
			<6354 6034 5400 5095 5050 5042>,
			<6396 6092 5427 5102 5056 5050>,
			<6454 6156 5462 5114 5066 5062>,
			<6512 6222 5507 5126 5079 5074>,
			<6581 6287 5551 5128 5083 5074>,
			<6675 6349 5590 5118 5065 5052>,
			<6822 6425 5643 5127 5060 5049>,
			<7246 6563 5767 5148 5065 5054>,
			<8416 6846 5976 5185 5078 5064>,
			<8416 6846 5976 5185 5078 5064>,
			<8416 6846 5976 5185 5078 5064>;
	};

};
